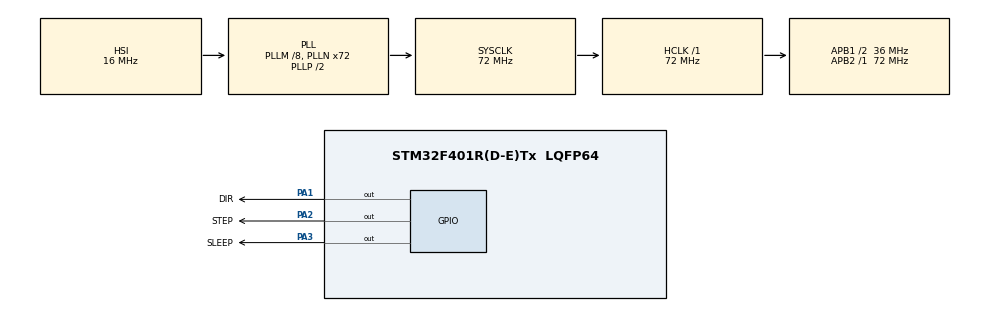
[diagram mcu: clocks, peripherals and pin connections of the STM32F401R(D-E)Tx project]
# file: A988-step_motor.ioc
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Mcu.Family=STM32F4
Mcu.Name=STM32F401R(D-E)Tx
Mcu.Package=LQFP64
NVIC.PriorityGroup=NVIC_PRIORITYGROUP_4
PA1.GPIO_Label=DIR
PA1.Signal=GPIO_Output
PA13.Mode=Serial_Wire
PA13.Signal=SYS_JTMS-SWDIO
PA14.Mode=Serial_Wire
PA14.Signal=SYS_JTCK-SWCLK
PA2.GPIO_Label=STEP
PA2.Signal=GPIO_Output
PA3.GPIO_Label=SLEEP
PA3.Signal=GPIO_Output
ProjectManager.HeapSize=0x200
ProjectManager.StackSize=0x400
ProjectManager.TargetToolchain=STM32CubeIDE
RCC.48MHZClocksFreq_Value=36000000
RCC.AHBFreq_Value=72000000
RCC.APB1CLKDivider=RCC_HCLK_DIV2
RCC.APB1Freq_Value=36000000
RCC.APB1TimFreq_Value=72000000
RCC.APB2Freq_Value=72000000
RCC.APB2TimFreq_Value=72000000
RCC.CortexFreq_Value=72000000
RCC.HCLKFreq_Value=72000000
RCC.HSE_VALUE=25000000
RCC.HSI_VALUE=16000000
RCC.LSE_VALUE=32768
RCC.PLLM=8
RCC.PLLN=72
RCC.SYSCLKFreq_VALUE=72000000
RCC.SYSCLKSource=RCC_SYSCLKSOURCE_PLLCLK
RCC.VCOOutputFreq_Value=144000000
TIM1.Prescaler=71
VP_TIM1_VS_ClockSourceINT.Mode=Internal
board=custom

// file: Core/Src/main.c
/* USER CODE BEGIN Header */
/**
  ******************************************************************************
  * @file           : main.c
  * @brief          : Main program body
  ******************************************************************************
  * @attention
  *
  * Copyright (c) 2023 STMicroelectronics.
  * All rights reserved.
  *
  * This software is licensed under terms that can be found in the LICENSE file
  * in the root directory of this software component.
  * If no LICENSE file comes with this software, it is provided AS-IS.
  *
  ******************************************************************************
  */
/* USER CODE END Header */
#include "main.h"
#include "tim.h"
#include "gpio.h"

/* USER CODE BEGIN Includes */
#include "A988.h"
#include "stdint.h"
/* USER CODE END Includes */

void SystemClock_Config(void);

/* USER CODE BEGIN 0 */
void microDelay (uint16_t delay)
{
  __HAL_TIM_SET_COUNTER(&htim1, 0);
  while (__HAL_TIM_GET_COUNTER(&htim1) < delay);
}
	int SLOW_SPEED=2000;
	int MEDIUM_SPEED=1500;
	int FAST_SPEED=1000;
/* USER CODE END 0 */

int main(void)
{

  /* MCU Configuration--------------------------------------------------------*/

  /* Reset of all peripherals, Initializes the Flash interface and the Systick. */
  HAL_Init();

  /* Configure the system clock */
  SystemClock_Config();

  /* Initialize all configured peripherals */
  MX_GPIO_Init();
  MX_TIM1_Init();
  /* USER CODE BEGIN 2 */
  HAL_TIM_Base_Start(&htim1);
  /* USER CODE END 2 */

  /* Infinite loop */
  /* USER CODE BEGIN WHILE */

  while (1)
  {
	  int x;
	  dir(SECOND_DIRICETION);
	  for(x=0; x<5000; x++)
	      {
	    	step(STEP);
	        microDelay(FAST_SPEED);
	        step(NOSTEP);
	        microDelay(FAST_SPEED);
	      }
	  int i;
	  	  dir(FIRST_DIRECTION);
	  	  for(i=0; i<5000; i++)
	  	      {
	  	    	step(STEP);
	  	        microDelay(FAST_SPEED);
	  	        step(NOSTEP);
	  	        microDelay(FAST_SPEED);
	  	      }

    /* USER CODE END WHILE */

  }
}

void SystemClock_Config(void)
{
  RCC_OscInitTypeDef RCC_OscInitStruct = {0};
  RCC_ClkInitTypeDef RCC_ClkInitStruct = {0};

  /** Configure the main internal regulator output voltage
  */
  __HAL_RCC_PWR_CLK_ENABLE();
  __HAL_PWR_VOLTAGESCALING_CONFIG(PWR_REGULATOR_VOLTAGE_SCALE2);
  /** Initializes the RCC Oscillators according to the specified parameters
  * in the RCC_OscInitTypeDef structure.
  */
  RCC_OscInitStruct.OscillatorType = RCC_OSCILLATORTYPE_HSI;
  RCC_OscInitStruct.HSIState = RCC_HSI_ON;
  RCC_OscInitStruct.HSICalibrationValue = RCC_HSICALIBRATION_DEFAULT;
  RCC_OscInitStruct.PLL.PLLState = RCC_PLL_ON;
  RCC_OscInitStruct.PLL.PLLSource = RCC_PLLSOURCE_HSI;
  RCC_OscInitStruct.PLL.PLLM = 8;
  RCC_OscInitStruct.PLL.PLLN = 72;
  RCC_OscInitStruct.PLL.PLLP = RCC_PLLP_DIV2;
  RCC_OscInitStruct.PLL.PLLQ = 4;
  if (HAL_RCC_OscConfig(&RCC_OscInitStruct) != HAL_OK)
  {
    Error_Handler();
  }
  /** Initializes the CPU, AHB and APB buses clocks
  */
  RCC_ClkInitStruct.ClockType = RCC_CLOCKTYPE_HCLK|RCC_CLOCKTYPE_SYSCLK
                              |RCC_CLOCKTYPE_PCLK1|RCC_CLOCKTYPE_PCLK2;
  RCC_ClkInitStruct.SYSCLKSource = RCC_SYSCLKSOURCE_PLLCLK;
  RCC_ClkInitStruct.AHBCLKDivider = RCC_SYSCLK_DIV1;
  RCC_ClkInitStruct.APB1CLKDivider = RCC_HCLK_DIV2;
  RCC_ClkInitStruct.APB2CLKDivider = RCC_HCLK_DIV1;

  if (HAL_RCC_ClockConfig(&RCC_ClkInitStruct, FLASH_LATENCY_2) != HAL_OK)
  {
    Error_Handler();
  }
}

void Error_Handler(void)
{
  __disable_irq();
  while (1)
  {
  }
}
